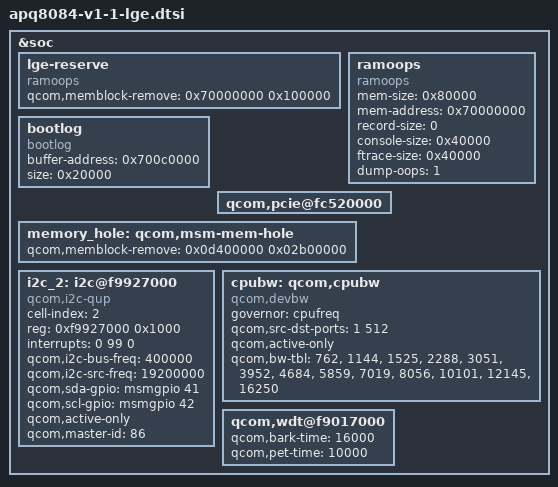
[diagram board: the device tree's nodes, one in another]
/* Copyright (c) 2012, Code Aurora Forum. All rights reserved.
 *
 * This program is free software; you can redistribute it and/or modify
 * it under the terms of the GNU General Public License version 2 and
 * only version 2 as published by the Free Software Foundation.
 *
 * This program is distributed in the hope that it will be useful,
 * but WITHOUT ANY WARRANTY; without even the implied warranty of
 * MERCHANTABILITY or FITNESS FOR A PARTICULAR PURPOSE.  See the
 * GNU General Public License for more details.
 */

#include "../../qcom/apq8084-v1.1.dtsi"
#include "../../qcom/apq8084-mtp.dtsi"

#include "apq8084-lge-input.dtsi"
#include "apq8084-lge-panel.dtsi"
#include "apq8084-lge-hdmi.dtsi"
#include "apq8084-lge-usb.dtsi"
#include "apq8084-lge-misc.dtsi"
#include "apq8084-lge-pm.dtsi"
#include "apq8084-lge-sensor.dtsi"
#include "apq8084-lge-sound.dtsi"
#include "apq8084-lge-camera.dtsi"
#include "apq8084-lge-mmc.dtsi"
#include "apq8084-lge-bt.dtsi"
#include "apq8084-lge-tdmb.dtsi"

&soc {
	/delete-node/ qcom,cnss@0d400000;

	/delete-node/ bt_qca6174;

	lge-reserve {
		compatible = "ramoops", "bootlog";
		qcom,memblock-remove = <0x70000000 0x100000>;
	};

	ramoops {
		compatible = "ramoops";
		mem-size = <0x80000>;
		mem-address = <0x70000000>;
		record-size = <0>;
		console-size = <0x40000>;
		ftrace-size = <0x40000>;
		dump-oops = <1>;
	};

	bootlog {
		compatible = "bootlog";
		buffer-address = <0x700c0000>;
		size = <0x20000>;
	};

	qcom,pcie@fc520000 {
		/delete-property/vreg-3.3-supply;
	};

	memory_hole: qcom,msm-mem-hole {
		/* 0x100000@0xfe00000 will be removed */
		qcom,memblock-remove = <0x0d400000 0x02b00000>;
	};

	i2c_2: i2c@f9927000 { /* BLSP1 QUP5 */
		cell-index = <2>;
		compatible = "qcom,i2c-qup";
		#address-cells = <1>;
		#size-cells = <0>;
		reg-names = "qup_phys_addr";
		reg = <0xf9927000 0x1000>;
		interrupt-names = "qup_err_intr";
		interrupts = <0 99 0>;
		qcom,i2c-bus-freq = <400000>;
		qcom,i2c-src-freq = <19200000>;
		qcom,sda-gpio = <&msmgpio 41 0>;
		qcom,scl-gpio = <&msmgpio 42 0>;
		qcom,active-only;
		qcom,master-id = <86>;
	};

	cpubw: qcom,cpubw {
		compatible = "qcom,devbw";
		governor = "cpufreq";
		qcom,src-dst-ports = <1 512>;
		qcom,active-only;
		qcom,bw-tbl =
			<   762 /*   50 MHz */ >,
			<  1144 /*   75 MHz */ >,
			<  1525 /*  100 MHz */ >,
			<  2288 /*  150 MHz */ >,
			<  3051 /*  200 MHz */ >,
			<  3952 /*  259 MHz */ >,
			<  4684 /*  307 MHz */ >,
			<  5859 /*  384 MHz */ >,
			<  7019 /*  460 MHz */ >,
			<  8056 /*  528 MHz */ >,
			< 10101 /*  662 MHz */ >,
			< 12145 /*  796 MHz */ >,
			< 16250 /* 1065 MHz */ >;
	};

	qcom,wdt@f9017000 {
		qcom,bark-time = <16000>;
		qcom,pet-time = <10000>;
	};
};
